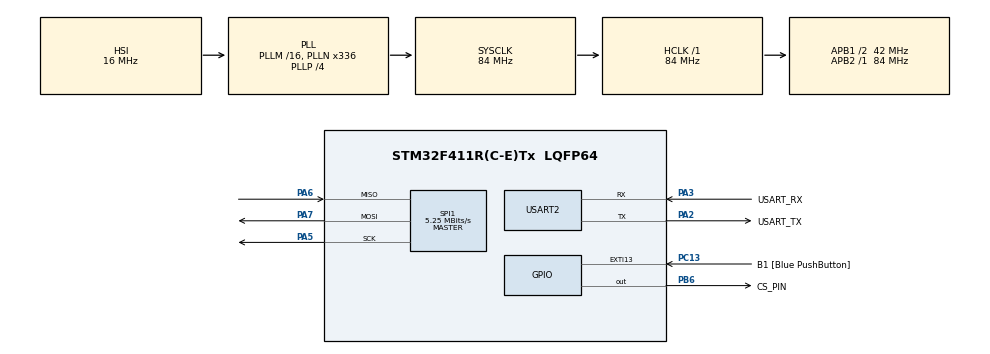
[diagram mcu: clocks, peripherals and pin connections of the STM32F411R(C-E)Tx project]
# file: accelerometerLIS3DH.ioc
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Mcu.Family=STM32F4
Mcu.Name=STM32F411R(C-E)Tx
Mcu.Package=LQFP64
NVIC.EXTI15_10_IRQn=true\:0\:0\:false\:false\:true\:true\:true\:true
NVIC.PriorityGroup=NVIC_PRIORITYGROUP_0
PA13.GPIO_Label=TMS
PA13.Mode=Serial_Wire
PA13.Signal=SYS_JTMS-SWDIO
PA14.GPIO_Label=TCK
PA14.Mode=Serial_Wire
PA14.Signal=SYS_JTCK-SWCLK
PA2.GPIO_Label=USART_TX
PA2.Mode=Asynchronous
PA2.Signal=USART2_TX
PA3.GPIO_Label=USART_RX
PA3.Mode=Asynchronous
PA3.Signal=USART2_RX
PA5.Mode=Full_Duplex_Master
PA5.Signal=SPI1_SCK
PA6.Mode=Full_Duplex_Master
PA6.Signal=SPI1_MISO
PA7.Mode=Full_Duplex_Master
PA7.Signal=SPI1_MOSI
PB6.GPIO_Label=CS_PIN
PB6.GPIO_Speed=GPIO_SPEED_FREQ_HIGH
PB6.PinState=GPIO_PIN_SET
PB6.Signal=GPIO_Output
PC13-ANTI_TAMP.GPIO_Label=B1 [Blue PushButton]
PC13-ANTI_TAMP.GPIO_ModeDefaultEXTI=GPIO_MODE_IT_FALLING
PC13-ANTI_TAMP.Signal=GPXTI13
PC14-OSC32_IN.Mode=LSE-External-Oscillator
PC14-OSC32_IN.Signal=RCC_OSC32_IN
PC15-OSC32_OUT.Mode=LSE-External-Oscillator
PC15-OSC32_OUT.Signal=RCC_OSC32_OUT
PH0\ -\ OSC_IN.Mode=HSE-External-Clock-Source
PH0\ -\ OSC_IN.Signal=RCC_OSC_IN
PH1\ -\ OSC_OUT.Mode=HSE-External-Clock-Source
PH1\ -\ OSC_OUT.Signal=RCC_OSC_OUT
ProjectManager.HeapSize=0x200
ProjectManager.StackSize=0x400
ProjectManager.TargetToolchain=STM32CubeIDE
RCC.48MHZClocksFreq_Value=84000000
RCC.AHBFreq_Value=84000000
RCC.APB1CLKDivider=RCC_HCLK_DIV2
RCC.APB1Freq_Value=42000000
RCC.APB1TimFreq_Value=84000000
RCC.APB2Freq_Value=84000000
RCC.APB2TimFreq_Value=84000000
RCC.CortexFreq_Value=84000000
RCC.FLatency-AdvancedSettings=FLASH_LATENCY_2
RCC.HCLKFreq_Value=84000000
RCC.HSE_VALUE=8000000
RCC.HSI_VALUE=16000000
RCC.PLLN=336
RCC.PLLP=RCC_PLLP_DIV4
RCC.SYSCLKFreq_VALUE=84000000
RCC.SYSCLKSource=RCC_SYSCLKSOURCE_PLLCLK
RCC.VCOOutputFreq_Value=336000000
SPI1.BaudRatePrescaler=SPI_BAUDRATEPRESCALER_16
SPI1.CLKPhase=SPI_PHASE_2EDGE
SPI1.CLKPolarity=SPI_POLARITY_HIGH
SPI1.CalculateBaudRate=5.25 MBits/s
SPI1.Direction=SPI_DIRECTION_2LINES
SPI1.Mode=SPI_MODE_MASTER
SPI1.VirtualType=VM_MASTER
USART2.VirtualMode=VM_ASYNC
board=NUCLEO-F411RE

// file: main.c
/* USER CODE BEGIN Header */
/**
  ******************************************************************************
  * @file           : main.c
  * @brief          : Main program body
  ******************************************************************************
  * @attention
  *
  * Copyright (c) 2026 STMicroelectronics.
  * All rights reserved.
  *
  * This software is licensed under terms that can be found in the LICENSE file
  * in the root directory of this software component.
  * If no LICENSE file comes with this software, it is provided AS-IS.
  *
  ******************************************************************************
  */
/* USER CODE END Header */
#include "main.h"
#include "lis3dh.h"
#include <stdio.h>

SPI_HandleTypeDef hspi1;
int16_t accel_x, accel_y, accel_z;

UART_HandleTypeDef huart2;

/* USER CODE BEGIN PV */
/* Private variables */
uint8_t TX_Buffer [] = "A" ; // DATA to send

//comment out for production, used for debugging and serial moniter
int _write(int file, char *ptr, int len)
{
    HAL_UART_Transmit(&huart2, (uint8_t *)ptr, len, HAL_MAX_DELAY);
    return len;
}

/* USER CODE END PV */

void SystemClock_Config(void);
static void MX_GPIO_Init(void);
static void MX_SPI1_Init(void);
static void MX_USART2_UART_Init(void);

int main(void)
{

  /* USER CODE BEGIN 1 */
	char uart_buf[100];
	int uart_buf_len;

  /* USER CODE END 1 */

  /* MCU Configuration--------------------------------------------------------*/

  /* Reset of all peripherals, Initializes the Flash interface and the Systick. */
  HAL_Init();

  /* Configure the system clock */
  SystemClock_Config();

  /* Initialize all configured peripherals */
  MX_GPIO_Init();
  MX_SPI1_Init();
  MX_USART2_UART_Init();

  //comment out for production, used for serial moniter
  if (!LIS3DH_Serial()) {
          while (1);  // halt if sensor not found
      }

  /* USER CODE BEGIN 2 */

  LIS3DH_Init();

  uint8_t whoami = LIS3DH_ReadReg(LIS3DH_WHO_AM_I);
  printf("WHO_AM_I = 0x%02X\r\n", whoami);

  //HAL_SPI_Transmit(&hspi1, TX_Buffer, 1, 1000); //Sending in Blocking mode
  HAL_Delay(100);

  /* USER CODE END 2 */

  /* Infinite loop */
  while (1)
  {
	  LIS3DH_ReadAccel(&accel_x, &accel_y, &accel_z);

	  //convert raw data into g's, must divide by 16000 because device measures in mili g's, and we have shifted the data by 4 bits left (multiply by 4)
	  //comment out if data doesn't need to be in g's
	  float x_g = accel_x/16000.0f;
	  float y_g = accel_y/16000.0f;
	  float z_g = accel_z/16000.0f;

	  printf("X=%0.3fg  Y=%0.3fg  Z=%0.3fg\r\n", x_g, y_g,  z_g);
	  HAL_Delay(100);
  }
}

void SystemClock_Config(void)
{
  RCC_OscInitTypeDef RCC_OscInitStruct = {0};
  RCC_ClkInitTypeDef RCC_ClkInitStruct = {0};

  /** Configure the main internal regulator output voltage
  */
  __HAL_RCC_PWR_CLK_ENABLE();
  __HAL_PWR_VOLTAGESCALING_CONFIG(PWR_REGULATOR_VOLTAGE_SCALE1);

  /** Initializes the RCC Oscillators according to the specified parameters
  * in the RCC_OscInitTypeDef structure.
  */
  RCC_OscInitStruct.OscillatorType = RCC_OSCILLATORTYPE_HSI;
  RCC_OscInitStruct.HSIState = RCC_HSI_ON;
  RCC_OscInitStruct.HSICalibrationValue = RCC_HSICALIBRATION_DEFAULT;
  RCC_OscInitStruct.PLL.PLLState = RCC_PLL_ON;
  RCC_OscInitStruct.PLL.PLLSource = RCC_PLLSOURCE_HSI;
  RCC_OscInitStruct.PLL.PLLM = 16;
  RCC_OscInitStruct.PLL.PLLN = 336;
  RCC_OscInitStruct.PLL.PLLP = RCC_PLLP_DIV4;
  RCC_OscInitStruct.PLL.PLLQ = 4;
  if (HAL_RCC_OscConfig(&RCC_OscInitStruct) != HAL_OK)
  {
    Error_Handler();
  }

  /** Initializes the CPU, AHB and APB buses clocks
  */
  RCC_ClkInitStruct.ClockType = RCC_CLOCKTYPE_HCLK|RCC_CLOCKTYPE_SYSCLK
                              |RCC_CLOCKTYPE_PCLK1|RCC_CLOCKTYPE_PCLK2;
  RCC_ClkInitStruct.SYSCLKSource = RCC_SYSCLKSOURCE_PLLCLK;
  RCC_ClkInitStruct.AHBCLKDivider = RCC_SYSCLK_DIV1;
  RCC_ClkInitStruct.APB1CLKDivider = RCC_HCLK_DIV2;
  RCC_ClkInitStruct.APB2CLKDivider = RCC_HCLK_DIV1;

  if (HAL_RCC_ClockConfig(&RCC_ClkInitStruct, FLASH_LATENCY_2) != HAL_OK)
  {
    Error_Handler();
  }
}

static void MX_SPI1_Init(void)
{

  /* SPI1 parameter configuration*/
  hspi1.Instance = SPI1;
  hspi1.Init.Mode = SPI_MODE_MASTER;
  hspi1.Init.Direction = SPI_DIRECTION_2LINES;
  hspi1.Init.DataSize = SPI_DATASIZE_8BIT;
  hspi1.Init.CLKPolarity = SPI_POLARITY_HIGH;
  hspi1.Init.CLKPhase = SPI_PHASE_2EDGE;
  hspi1.Init.NSS = SPI_NSS_SOFT;
  hspi1.Init.BaudRatePrescaler = SPI_BAUDRATEPRESCALER_16;
  hspi1.Init.FirstBit = SPI_FIRSTBIT_MSB;
  hspi1.Init.TIMode = SPI_TIMODE_DISABLE;
  hspi1.Init.CRCCalculation = SPI_CRCCALCULATION_DISABLE;
  hspi1.Init.CRCPolynomial = 10;
  if (HAL_SPI_Init(&hspi1) != HAL_OK)
  {
    Error_Handler();
  }

}

static void MX_USART2_UART_Init(void)
{

  huart2.Instance = USART2;
  huart2.Init.BaudRate = 115200;
  huart2.Init.WordLength = UART_WORDLENGTH_8B;
  huart2.Init.StopBits = UART_STOPBITS_1;
  huart2.Init.Parity = UART_PARITY_NONE;
  huart2.Init.Mode = UART_MODE_TX_RX;
  huart2.Init.HwFlowCtl = UART_HWCONTROL_NONE;
  huart2.Init.OverSampling = UART_OVERSAMPLING_16;
  if (HAL_UART_Init(&huart2) != HAL_OK)
  {
    Error_Handler();
  }

}

static void MX_GPIO_Init(void)
{
  GPIO_InitTypeDef GPIO_InitStruct = {0};

  /* GPIO Ports Clock Enable */
  __HAL_RCC_GPIOC_CLK_ENABLE();
  __HAL_RCC_GPIOH_CLK_ENABLE();
  __HAL_RCC_GPIOA_CLK_ENABLE();
  __HAL_RCC_GPIOB_CLK_ENABLE();

  /*Configure GPIO pin Output Level */
  HAL_GPIO_WritePin(CS_PIN_GPIO_Port, CS_PIN_Pin, GPIO_PIN_SET);

  /*Configure GPIO pin : B1_Pin */
  GPIO_InitStruct.Pin = B1_Pin;
  GPIO_InitStruct.Mode = GPIO_MODE_IT_FALLING;
  GPIO_InitStruct.Pull = GPIO_NOPULL;
  HAL_GPIO_Init(B1_GPIO_Port, &GPIO_InitStruct);

  /*Configure GPIO pin : CS_PIN_Pin */
  GPIO_InitStruct.Pin = CS_PIN_Pin;
  GPIO_InitStruct.Mode = GPIO_MODE_OUTPUT_PP;
  GPIO_InitStruct.Pull = GPIO_NOPULL;
  GPIO_InitStruct.Speed = GPIO_SPEED_FREQ_HIGH;
  HAL_GPIO_Init(CS_PIN_GPIO_Port, &GPIO_InitStruct);

  /* EXTI interrupt init*/
  HAL_NVIC_SetPriority(EXTI15_10_IRQn, 0, 0);
  HAL_NVIC_EnableIRQ(EXTI15_10_IRQn);

}

void Error_Handler(void)
{
  __disable_irq();
  while (1)
  {
  }
}
